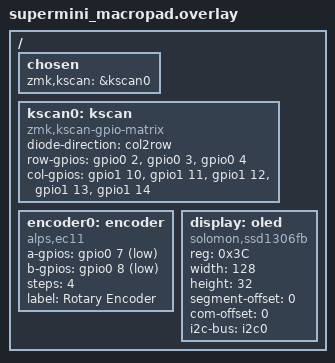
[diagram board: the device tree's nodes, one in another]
/ {
    chosen {
        zmk,kscan = &kscan0;
    };

    kscan0: kscan {
        compatible = "zmk,kscan-gpio-matrix";
        diode-direction = "col2row";
        row-gpios = <&gpio0 2 (GPIO_ACTIVE_HIGH)>,
                    <&gpio0 3 (GPIO_ACTIVE_HIGH)>,
                    <&gpio0 4 (GPIO_ACTIVE_HIGH)>;
        col-gpios = <&gpio1 10 (GPIO_ACTIVE_HIGH)>,
                    <&gpio1 11 (GPIO_ACTIVE_HIGH)>,
                    <&gpio1 12 (GPIO_ACTIVE_HIGH)>,
                    <&gpio1 13 (GPIO_ACTIVE_HIGH)>,
                    <&gpio1 14 (GPIO_ACTIVE_HIGH)>;
    };

    encoder0: encoder {
        compatible = "alps,ec11";
        a-gpios = <&gpio0 7 (GPIO_ACTIVE_LOW)>;
        b-gpios = <&gpio0 8 (GPIO_ACTIVE_LOW)>;
        steps = <4>;
        label = "Rotary Encoder";
    };

    display: oled {
        compatible = "solomon,ssd1306fb";
        reg = <0x3C>;
        width = <128>;
        height = <32>;
        segment-offset = <0>;
        com-offset = <0>;
        i2c-bus = <&i2c0>;
    };
};
